# SCSCS register map
Vendor: Texas Instruments
Peripheral module from a debugger description file (folder CC23x0R5).
Registers are 32-bit, read-only, reset 0x0 unless marked. A register's access mark holds for its fields unless they carry their own. Offsets are as the file gives them; lines under a group give offsets from that group; [hi:lo] are bit positions; {n}, {i} and the like mark numbered series; 'fields as' and 'values as' point back to an identical list; <NAME> marks a mode.

## SCSCS
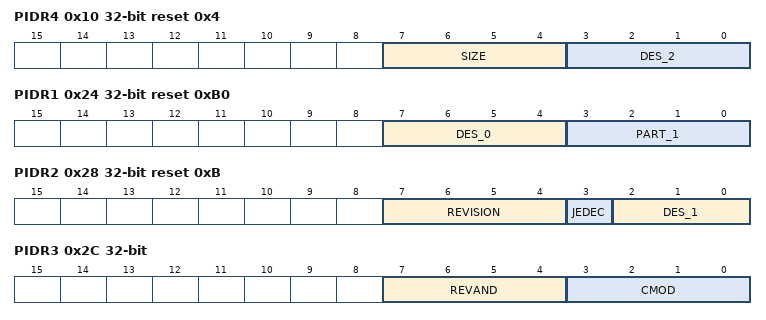
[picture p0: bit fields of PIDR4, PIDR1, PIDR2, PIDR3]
0x10 PIDR4 reset 0x4 — Peripheral ID Register 4 Part of the set of Peripheral Identification registers. Contains part of the designer identity and the memory footprint indicator.
  [7:4] SIZE — This is a 4-bit value that indicates the total contiguous size of the memory window used by this component in powers of 2 from the standard 4KB. If a component only requires the standard 4KB then this should read as 0x0, 4KB only, for 8KB set to 0x1, 16KB == 0x2, 32KB == 0x3, and so on.
  [3:0] DES_2 — Number of JEDEC continuation codes. Indicates the designer of the component (along with the identity code)
{0x0+4i} PIDR{i} (i=5..7) — Peripheral ID Register {i} Reserved
0x20 PIDR0 reset 0x8 — Peripheral ID Register 0 Part of the set of Peripheral Identification registers. Contains part of the designer specific part number.
  [7:0] PART_0 — Bits [7:0] of the component's part number. This is selected by the designer of the component.
0x24 PIDR1 reset 0xB0 — Peripheral ID Register 1 Part of the set of Peripheral Identification registers. Contains part of the designer specific part number and part of the designer identity.
  [7:4] DES_0 — Bits [3:0] of the JEDEC identity code indicating the designer of the component (along with the continuation code)
  [3:0] PART_1 — Bits [11:8] of the component's part number. This is selected by the designer of the component.
0x28 PIDR2 reset 0xB — Peripheral ID Register 2 Part of the set of Peripheral Identification registers. Contains part of the designer identity and the product revision.
  [7:4] REVISION — The Revision field is an incremental value starting at 0x0 for the first design of this component. This only increases by 1 for both major and minor revisions and is simply used as a look-up to establish the exact major/minor revision.
  [3] JEDEC — Always set. Indicates that a JEDEC assigned value is used
  [2:0] DES_1 — Bits [6:4] of the JEDEC identity code indicating the designer of the component (along with the continuation code)
0x2C PIDR3 — Peripheral ID Register 3 Part of the set of Peripheral Identification registers. Contains the RevAnd and Customer Modified fields.
  [7:4] REVAND — This field indicates minor errata fixes specific to this design, for example metal fixes after implementation. In most cases this field is zero. It is recommended that component designers ensure this field can be changed by a metal fix if required, for example by driving it from registers that reset to zero.
  [3:0] CMOD — Where the component is reusable IP, this value indicates if the customer has modified the behavior of the component. In most cases this field is zero.
0x30 CIDR0 reset 0xD — Component ID Register 0 A component identification register, that indicates that the identification registers are present.
  [7:0] PRMBL_0 — Contains bits [7:0] of the component identification
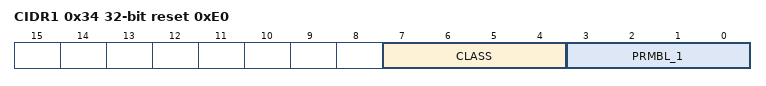
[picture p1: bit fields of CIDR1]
0x34 CIDR1 reset 0xE0 — Component ID Register 1 A component identification register, that indicates that the identification registers are present. This register also indicates the component class.
  [7:4] CLASS — Class of the component. E.g. ROM table, CoreSight component etc. Constitutes bits [15:12] of the component identification.
  [3:0] PRMBL_1 — Contains bits [11:8] of the component identification
0x38 CIDR2 reset 0x5 — Component ID Register 2 A component identification register, that indicates that the identification registers are present.
  [7:0] PRMBL_2 — Contains bits [23:16] of the component identification
0x3C CIDR3 reset 0xB1 — Component ID Register 3 A component identification register, that indicates that the identification registers are present.
  [7:0] PRMBL_3 — Contains bits [31:24] of the component identification
